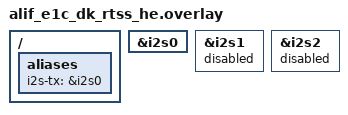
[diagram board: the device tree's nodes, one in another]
/*
 * Copyright (c) 2024 Alif Semiconductor.
 * SPDX-License-Identifier: Apache-2.0
 */

/*
 * I2S_0 => Output to Codec.
 * I2S_2 => Mic Input
 */

/ {
	aliases {
		i2s-tx = &i2s0;

	};
};

&i2s0 {
	status = "okay";
};

&i2s1 {
	status = "disabled";
};

&i2s2 {
	status = "disabled";
};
